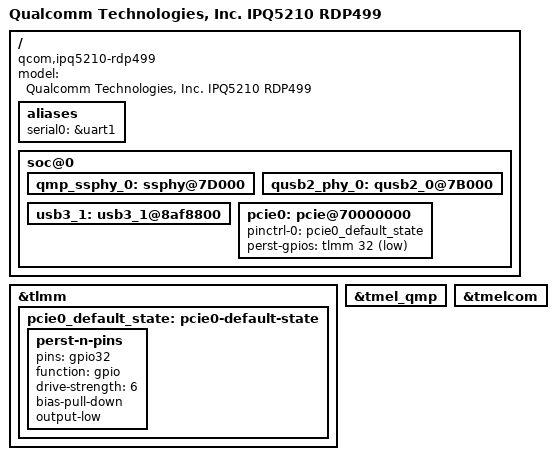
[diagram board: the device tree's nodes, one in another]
// SPDX-License-Identifier: GPL-2.0-only
/*
 * Copyright (c) Qualcomm Technologies, Inc. and/or its subsidiaries.
 */

/dts-v1/;

#include "ipq5210-u-boot.dtsi"

/ {
	model = "Qualcomm Technologies, Inc. IPQ5210 RDP499";
	compatible = "qcom,ipq5210-rdp499", "qcom,ipq5210";

	aliases {
		serial0 = &uart1;
	};

	soc@0 {
		qmp_ssphy_0: ssphy@7D000 {
			status = "okay";
		};

		qusb2_phy_0: qusb2_0@7B000 {
			status = "okay";
		};

		usb3_1: usb3_1@8af8800 {
			status = "okay";
		};

		pcie0: pcie@70000000 {
			pinctrl-0 = <&pcie0_default_state>;
			pinctrl-names = "default";
			perst-gpios = <&tlmm 32 GPIO_ACTIVE_LOW>;
			status = "okay";
		};
	};
};

&tlmm {
	pcie0_default_state: pcie0-default-state {
		perst-n-pins {
			pins = "gpio32";
			function = "gpio";
			drive-strength = <6>;
			bias-pull-down;
			output-low;
		};
	};
};

&tmel_qmp {
	status = "okay";
};

&tmelcom {
	status = "okay";
};
